AUTOSAR XML (schema 4-0-3)
standard types defined: Boolean, UInt8
package /AUTOSAR_Platform/DataConstrs
  range DC_Boolean: raw 0..1
package /PATAC/Facility/DataTypes/Implementation
  unit NoUnit: factor-si-to-unit=1, offset-si-to-unit=0
package /PATAC/MSM/ComponentTypes
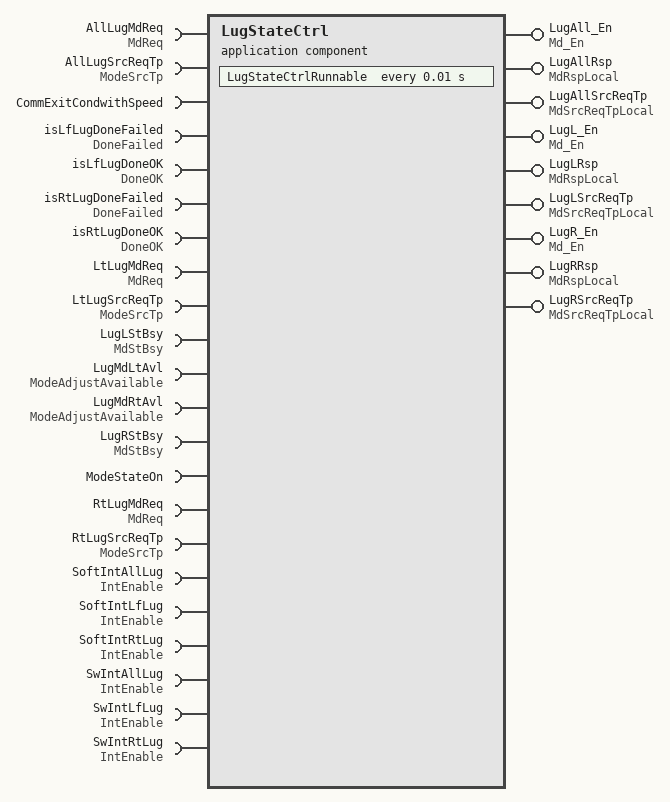
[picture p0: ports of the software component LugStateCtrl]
  application sw component type LugStateCtrl
    9 x provide port:
      LugAll_En: nonqueued-sender-com-spec{data-element=Md_En/Val, init-value=0}, provided-interface=Md_En
      LugAllRsp: nonqueued-sender-com-spec{data-element=MdRspLocal/Val, init-value=0}, provided-interface=MdRspLocal
      LugAllSrcReqTp: nonqueued-sender-com-spec{data-element=MdSrcReqTpLocal/Val, init-value=0}, provided-interface=MdSrcReqTpLocal
      LugL_En: nonqueued-sender-com-spec{data-element=Md_En/Val, init-value=0}, provided-interface=Md_En
      LugLRsp: nonqueued-sender-com-spec{data-element=MdRspLocal/Val, init-value=0}, provided-interface=MdRspLocal
      LugLSrcReqTp: nonqueued-sender-com-spec{data-element=MdSrcReqTpLocal/Val, init-value=0}, provided-interface=MdSrcReqTpLocal
      LugR_En: nonqueued-sender-com-spec{data-element=Md_En/Val, init-value=0}, provided-interface=Md_En
      LugRRsp: nonqueued-sender-com-spec{data-element=MdRspLocal/Val, init-value=0}, provided-interface=MdRspLocal
      LugRSrcReqTp: nonqueued-sender-com-spec{data-element=MdSrcReqTpLocal/Val, init-value=0}, provided-interface=MdSrcReqTpLocal
    22 x require port:
      AllLugMdReq: nonqueued-receiver-com-spec{data-element=MdReq/Val, filter=data-filter-type=ALWAYS, init-value=0}, required-interface=MdReq
      AllLugSrcReqTp: nonqueued-receiver-com-spec{data-element=ModeSrcTp/Val, filter=data-filter-type=ALWAYS, init-value=0}, required-interface=ModeSrcTp
      CommExitCondwithSpeed: nonqueued-receiver-com-spec{data-element=CommExitCondwithSpeed/Val, filter=data-filter-type=ALWAYS, init-value=0}, required-interface=CommExitCondwithSpeed
      isLfLugDoneFailed: nonqueued-receiver-com-spec{data-element=DoneFailed/Val, filter=data-filter-type=ALWAYS, init-value=0}, required-interface=DoneFailed
      isLfLugDoneOK: nonqueued-receiver-com-spec{data-element=DoneOK/Val, filter=data-filter-type=ALWAYS, init-value=0}, required-interface=DoneOK
      isRtLugDoneFailed: nonqueued-receiver-com-spec{data-element=DoneFailed/Val, filter=data-filter-type=ALWAYS, init-value=0}, required-interface=DoneFailed
      isRtLugDoneOK: nonqueued-receiver-com-spec{data-element=DoneOK/Val, filter=data-filter-type=ALWAYS, init-value=0}, required-interface=DoneOK
      LtLugMdReq: nonqueued-receiver-com-spec{data-element=MdReq/Val, filter=data-filter-type=ALWAYS, init-value=0}, required-interface=MdReq
      LtLugSrcReqTp: nonqueued-receiver-com-spec{data-element=ModeSrcTp/Val, filter=data-filter-type=ALWAYS, init-value=0}, required-interface=ModeSrcTp
      LugLStBsy: nonqueued-receiver-com-spec{data-element=MdStBsy/Val, filter=data-filter-type=ALWAYS, init-value=0}, required-interface=MdStBsy
      LugMdLtAvl: nonqueued-receiver-com-spec{data-element=ModeAdjustAvailable/Val, filter=data-filter-type=ALWAYS, init-value=0}, required-interface=ModeAdjustAvailable
      LugMdRtAvl: nonqueued-receiver-com-spec{data-element=ModeAdjustAvailable/Val, filter=data-filter-type=ALWAYS, init-value=0}, required-interface=ModeAdjustAvailable
      LugRStBsy: nonqueued-receiver-com-spec{data-element=MdStBsy/Val, filter=data-filter-type=ALWAYS, init-value=0}, required-interface=MdStBsy
      ModeStateOn: nonqueued-receiver-com-spec{data-element=ModeStateOn/Val, filter=data-filter-type=ALWAYS, init-value=0}, required-interface=ModeStateOn
      RtLugMdReq: nonqueued-receiver-com-spec{data-element=MdReq/Val, filter=data-filter-type=ALWAYS, init-value=0}, required-interface=MdReq
      RtLugSrcReqTp: nonqueued-receiver-com-spec{data-element=ModeSrcTp/Val, filter=data-filter-type=ALWAYS, init-value=0}, required-interface=ModeSrcTp
      SoftIntAllLug: nonqueued-receiver-com-spec{data-element=IntEnable/Val, filter=data-filter-type=ALWAYS, init-value=0}, required-interface=IntEnable
      SoftIntLfLug: nonqueued-receiver-com-spec{data-element=IntEnable/Val, filter=data-filter-type=ALWAYS, init-value=0}, required-interface=IntEnable
      SoftIntRtLug: nonqueued-receiver-com-spec{data-element=IntEnable/Val, filter=data-filter-type=ALWAYS, init-value=0}, required-interface=IntEnable
      SwIntAllLug: nonqueued-receiver-com-spec{data-element=IntEnable/Val, filter=data-filter-type=ALWAYS, init-value=0}, required-interface=IntEnable
      SwIntLfLug: nonqueued-receiver-com-spec{data-element=IntEnable/Val, filter=data-filter-type=ALWAYS, init-value=0}, required-interface=IntEnable
      SwIntRtLug: nonqueued-receiver-com-spec{data-element=IntEnable/Val, filter=data-filter-type=ALWAYS, init-value=0}, required-interface=IntEnable
    behavior LugStateCtrl_InternalBehavior
      timing event TMT_EZEStateCtrlRunnable: start-on-event=LugStateCtrlRunnable, period=0.01
      runnable LugStateCtrlRunnable
        data-receive-point-by-arguments:
          22 x access:
            REC_AllLugMdReq_Val: accessed-variable=AllLugMdReq.Val
            REC_AllLugSrcReqTp_Val: accessed-variable=AllLugSrcReqTp.Val
            REC_CommExitCondwithSpeed_Val: accessed-variable=CommExitCondwithSpeed.Val
            REC_EZEStBsy_Val: accessed-variable=LugLStBsy.Val
            REC_isLfLugDoneFailed_Val: accessed-variable=isLfLugDoneFailed.Val
            REC_isLfLugDoneOK_Val: accessed-variable=isLfLugDoneOK.Val
            REC_isRtLugDoneFailed_Val: accessed-variable=isRtLugDoneFailed.Val
            REC_isRtLugDoneOK_Val: accessed-variable=isRtLugDoneOK.Val
            REC_LtLugMdReq_Val: accessed-variable=LtLugMdReq.Val
            REC_LtLugSrcReqTp_Val: accessed-variable=LtLugSrcReqTp.Val
            REC_LugMdLtAvl_Val: accessed-variable=LugMdLtAvl.Val
            REC_LugMdRtAvl_Val: accessed-variable=LugMdRtAvl.Val
            REC_LugRStBsy_Val: accessed-variable=LugRStBsy.Val
            REC_ModeStateOn_Val: accessed-variable=ModeStateOn.Val
            REC_RtLugMdReq_Val: accessed-variable=RtLugMdReq.Val
            REC_RtLugSrcReqTp_Val: accessed-variable=RtLugSrcReqTp.Val
            REC_SoftIntAllLug_Val: accessed-variable=SoftIntAllLug.Val
            REC_SoftIntLfLug_Val: accessed-variable=SoftIntLfLug.Val
            REC_SoftIntRtLug_Val: accessed-variable=SoftIntRtLug.Val
            REC_SwIntAllLug_Val: accessed-variable=SwIntAllLug.Val
            REC_SwIntLfLug_Val: accessed-variable=SwIntLfLug.Val
            REC_SwIntRtLug_Val: accessed-variable=SwIntRtLug.Val
        data-send-points:
          9 x access:
            SEND_EZQ_En_Val: accessed-variable=LugL_En.Val
            SEND_EZQRsp_Val: accessed-variable=LugLRsp.Val
            SEND_EZQSrcReqTp_Val: accessed-variable=LugLSrcReqTp.Val
            SEND_LugAll_En_Val: accessed-variable=LugAll_En.Val
            SEND_LugAllRsp_Val: accessed-variable=LugAllRsp.Val
            SEND_LugAllSrcReqTp_Val: accessed-variable=LugAllSrcReqTp.Val
            SEND_LugR_En_Val: accessed-variable=LugR_En.Val
            SEND_LugRRsp_Val: accessed-variable=LugRRsp.Val
            SEND_LugRSrcReqTp_Val: accessed-variable=LugRSrcReqTp.Val
  swc implementation LugStateCtrl_Implementation: behavior=LugStateCtrl_InternalBehavior
    code-descriptors:
      code Default: artifact-descriptors=autosar-engineering-object={short-label=Default, category=SWSRC}
package /PATAC/MSM/DataTypes/ImplementationDataTypes
  impl type IntEnable: category=VALUE, base-type=Boolean, sw-calibration-access=READ-ONLY, type-emitter=RTE
package /PATAC/MSM/ModeAdjust/DataType
  impl type MdRspLocal1: category=VALUE, base-type=UInt8, sw-calibration-access=READ-ONLY, compu {0=MdRsp_None, 1=MdRsp_RecallSuccessfully, 2=MdRsp_RecallUnsuccessfully_LocalInterrupt, 3=MdRsp_RecallUnsuccessfully_Error, 4=MdRsp_RecallOngoing, 5=MdRsp_RecallHalt}, type-emitter=RTE
  impl type SrcReqTp1: category=VALUE, base-type=UInt8, sw-calibration-access=READ-ONLY, compu {0=SrcReqTp_None, 1=SrcReqTp_Local, 2=SrcReqTp_HMI2L, 3=SrcReqTp_HMI2R, 4=SrcReqTp_HMI, 5=SrcReqTp_Remote, 6=SrcReqTp_SRS}, type-emitter=RTE
package /PATAC/MSM/ModeAdjust/PortInterface
  12 x sender receiver interface:
    CommExitCondwithSpeed: invalidation-policy{data-element=CommExitCondwithSpeed/Val, handle-invalid=DONT-INVALIDATE}
      data Val: type=Boolean
    DoneFailed: invalidation-policy{data-element=DoneFailed/Val, handle-invalid=DONT-INVALIDATE}
      data Val: type=Boolean
    DoneOK: invalidation-policy{data-element=DoneOK/Val, handle-invalid=DONT-INVALIDATE}
      data Val: type=Boolean
    IntEnable: invalidation-policy{data-element=IntEnable/Val, handle-invalid=DONT-INVALIDATE}
      data Val: type=IntEnable
    Md_En: invalidation-policy{data-element=Md_En/Val, handle-invalid=DONT-INVALIDATE}
      data Val: type=Boolean
    MdReq: invalidation-policy{data-element=MdReq/Val, handle-invalid=DONT-INVALIDATE}
      data Val: type=Boolean
    MdRspLocal: invalidation-policy{data-element=MdRspLocal/Val, handle-invalid=DONT-INVALIDATE}
      data Val: type=MdRspLocal1
    MdSrcReqTpLocal: invalidation-policy{data-element=MdSrcReqTpLocal/Val, handle-invalid=DONT-INVALIDATE}
      data Val: type=SrcReqTp1
    MdStBsy: invalidation-policy{data-element=MdStBsy/Val, handle-invalid=DONT-INVALIDATE}
      data Val: type=Boolean
    ModeAdjustAvailable: invalidation-policy{data-element=ModeAdjustAvailable/Val, handle-invalid=DONT-INVALIDATE}
      data Val: type=Boolean
    ModeSrcTp: invalidation-policy{data-element=ModeSrcTp/Val, handle-invalid=DONT-INVALIDATE}
      data Val: type=SrcReqTp1
    ModeStateOn: invalidation-policy{data-element=ModeStateOn/Val, handle-invalid=DONT-INVALIDATE}
      data Val: type=Boolean
